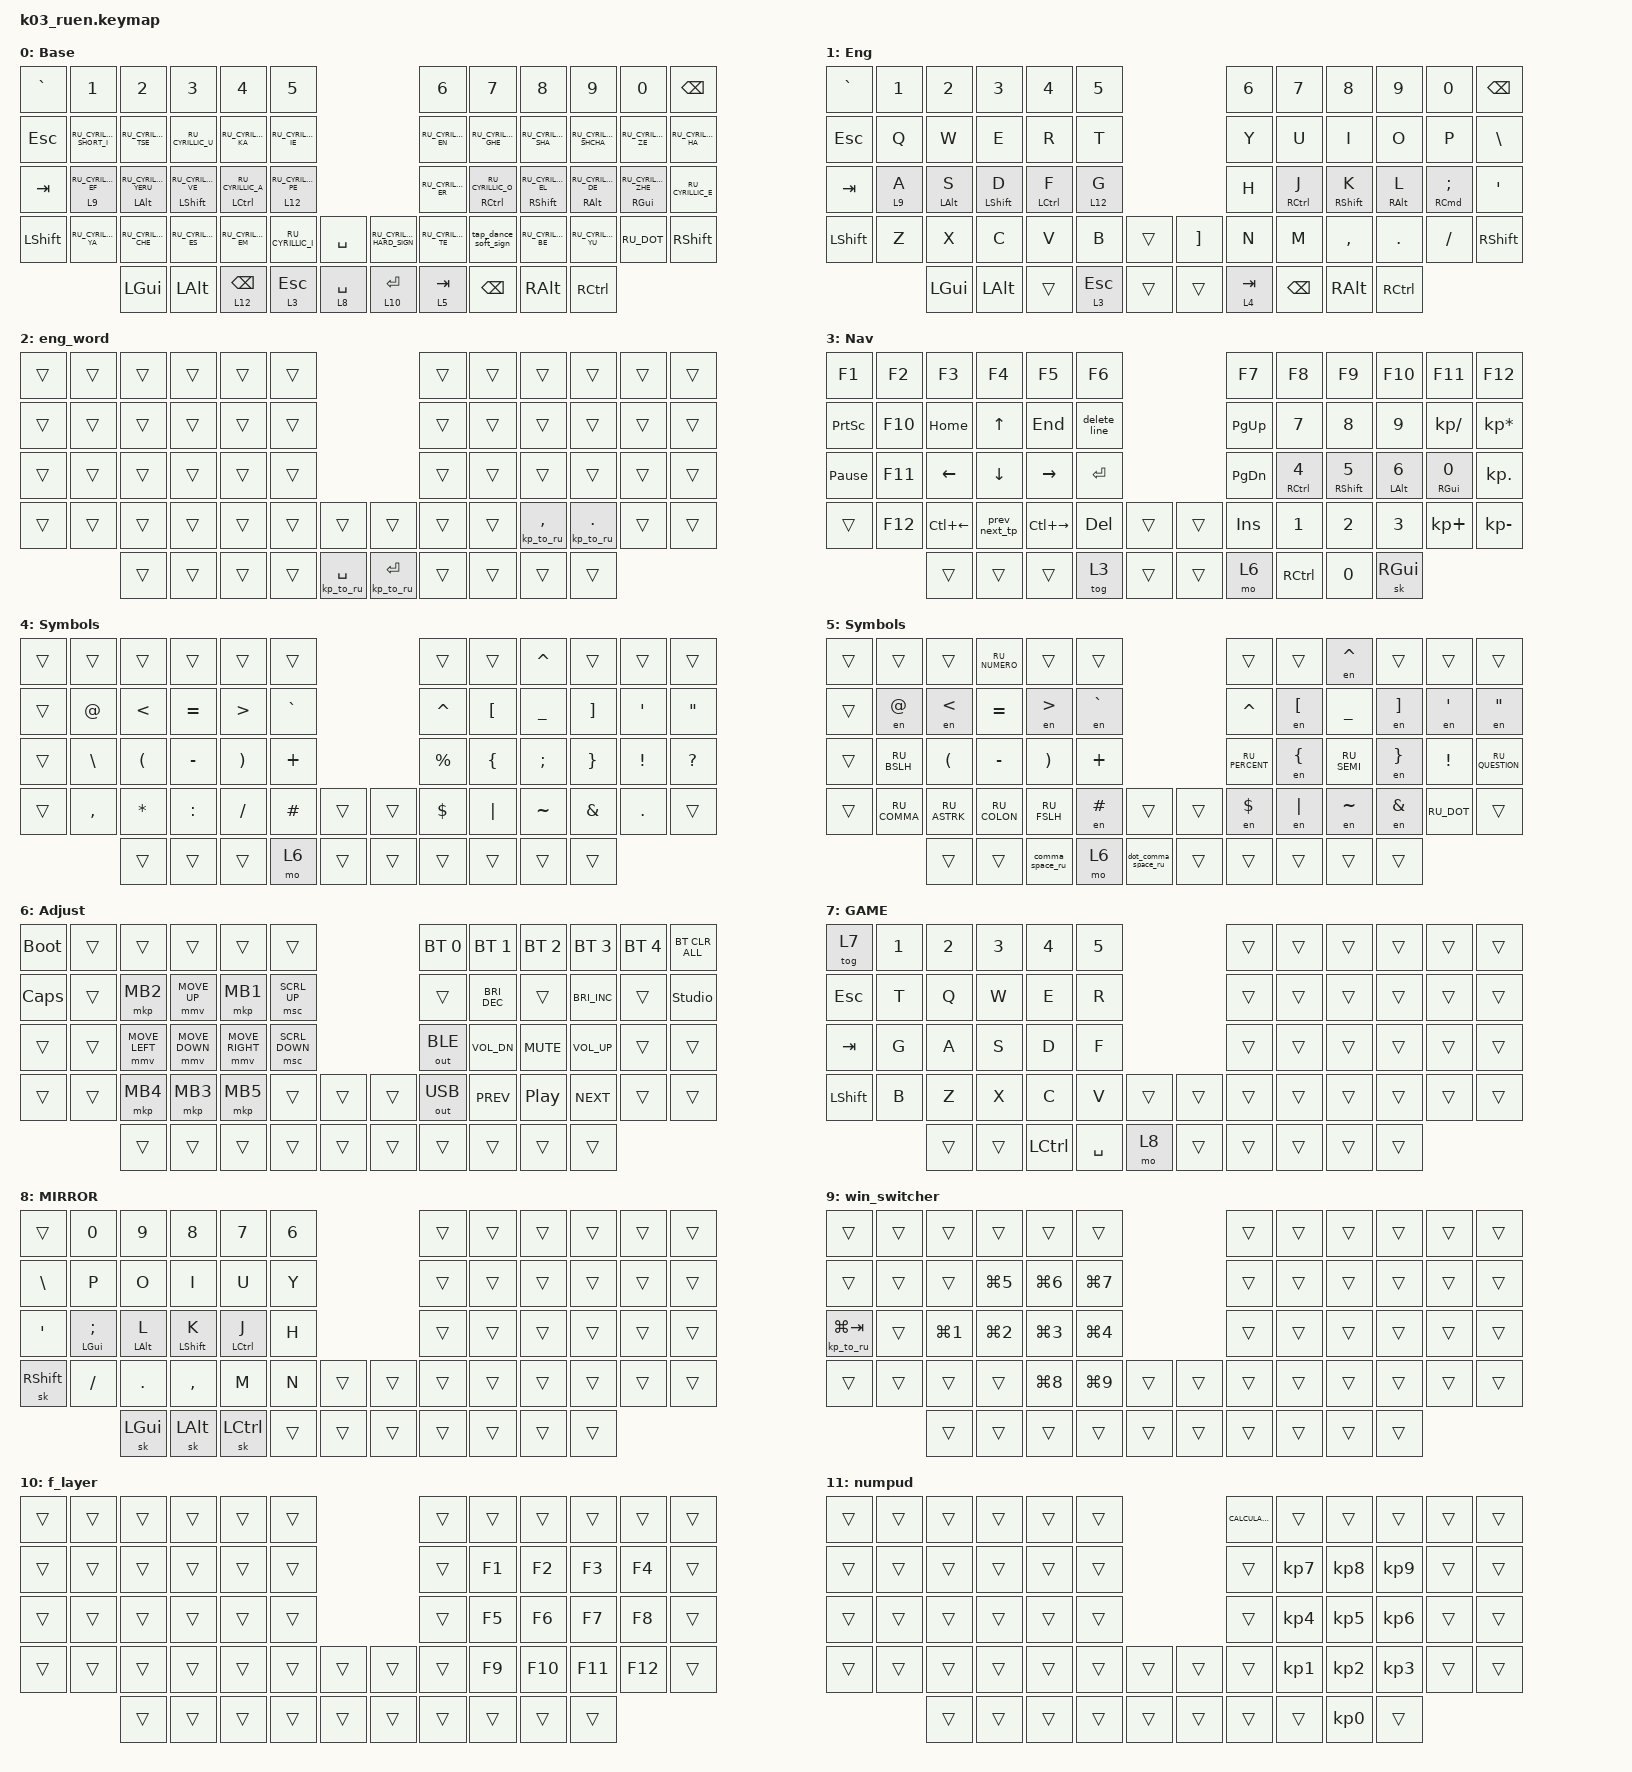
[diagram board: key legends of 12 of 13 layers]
#include "keys_ru.h"
#include <behaviors.dtsi>
#include <dt-bindings/zmk/bt.h>
#include <dt-bindings/zmk/keys.h>
#include <dt-bindings/zmk/outputs.h>
#include <dt-bindings/zmk/pointing.h>

&lt { flavor = "hold-preferred"; };

&mt { quick-tap-ms = <175>; };

/ {
    behaviors {
        enc_vol: enc_vol {
            compatible = "zmk,behavior-sensor-rotate";
            label = "ENC_VOL";
            #sensor-binding-cells = <0>;
            bindings = <&kp C_VOL_UP>, <&kp C_VOL_DN>;
        };

        l_st: l_st {
            compatible = "zmk,behavior-hold-tap";
            label = "L_ST";
            bindings = <&mo>, <&sk>;

            #binding-cells = <2>;
            tapping-term-ms = <200>;
        };

        prev_next: prev_next {
            compatible = "zmk,behavior-sensor-rotate";
            label = "PREV_NEXT";
            #sensor-binding-cells = <0>;
            bindings = <&mkp MB5>, <&mkp MB4>;
        };

        tap_dance_soft_sign: tap_dance_soft_sign {
            compatible = "zmk,behavior-tap-dance";
            label = "TAP_DANCE_SOFT_SIGN";
            #binding-cells = <0>;
            bindings = <&kp RU_CYRILLIC_SOFT_SIGN>, <&kp RU_CYRILLIC_HARD_SIGN>;
        };

        dot_comma_space_ru: dot_comma_space_ru {
            compatible = "zmk,behavior-tap-dance";
            label = "DOT_COMMA_SPACE_RU";
            #binding-cells = <0>;
            bindings = <&new_sentense_ru>, <&comma_space_ru>;
        };

        hml: home_row_mod_left {
            compatible = "zmk,behavior-hold-tap";
            label = "HML";
            bindings = <&kp>, <&kp>;

            #binding-cells = <2>;
            hold-trigger-on-release;
            hold-trigger-key-positions = <6 7 8 9 10 11 18 19 20 21 22 23 30 31 32 33 34 35 43 44 45 46 47 48 49 55 56 57 58 59 52 53 54>;
            flavor = "balanced";
            tapping-term-ms = <200>;
            quick-tap-ms = <175>;
            require-prior-idle-ms = <150>;
        };

        hmr: home_row_mod_right {
            compatible = "zmk,behavior-hold-tap";
            label = "HMR";
            bindings = <&kp>, <&kp>;

            #binding-cells = <2>;
            hold-trigger-on-release;
            flavor = "balanced";
            tapping-term-ms = <200>;
            quick-tap-ms = <175>;
            require-prior-idle-ms = <150>;
            hold-trigger-key-positions = <0 1 2 3 4 5 12 13 14 15 16 17 24 25 26 27 28 29 36 37 38 39 40 41 42 50 51 52 53 54 55 56 57>;
        };

        toggle_layer_on: toggle_layer_on {
            compatible = "zmk,behavior-toggle-layer";
            label = "TOGGLE_LAYER_ON";
            #binding-cells = <1>;
            toggle-mode = "on";
        };

        space_tp: space_tp {
            compatible = "zmk,behavior-tap-dance";
            label = "SPACE_TP";
            #binding-cells = <0>;
            bindings = <&lt 8 SPACE>, <&kp SPACE>;
        };

        lt_tap_pref: lt_tap_pref {
            compatible = "zmk,behavior-hold-tap";
            label = "LT_TAP_PREF";
            bindings = <&mo>, <&kp>;

            #binding-cells = <2>;
            flavor = "tap-preferred";
            tapping-term-ms = <200>;
            quick-tap-ms = <175>;
            require-prior-idle-ms = <150>;
        };

        sm_t: sm_t {
            compatible = "zmk,behavior-hold-tap";
            label = "SM_T";
            bindings = <&sk>, <&kp>;

            #binding-cells = <2>;
            flavor = "tap-preferred";
            tapping-term-ms = <200>;
            quick-tap-ms = <175>;
            require-prior-idle-ms = <150>;
        };

        caps_word_ru: caps_word_ru {
            compatible = "zmk,behavior-caps-word";
            label = "CAPS_WORD_RU";
            #binding-cells = <0>;
            continue-list = <UNDERSCORE MINUS BACKSPACE SEMI SQT COMMA DOT LBRC RBRC GRAVE>;
        };

        prev_next_tp: prev_next_tp {
            compatible = "zmk,behavior-tap-dance";
            label = "PREV_NEXT_TP";
            #binding-cells = <0>;
            bindings = <&mkp MB4>, <&mkp MB5>;
        };

        lt_quick_tap: lt_quick_tap {
            compatible = "zmk,behavior-hold-tap";
            label = "LT_QUICK_TAP";
            bindings = <&mo>, <&kp>;

            #binding-cells = <2>;
            tapping-term-ms = <200>;
            quick-tap-ms = <175>;
            flavor = "balanced";
        };
    };

    combos {
        compatible = "zmk,combos";

        cmben {
            bindings = <&layer_en>;
            key-positions = <40 41>;
            layers = <0>;
        };

        cmbru {
            bindings = <&layer_ru>;
            key-positions = <40 41>;
            layers = <1 2>;
        };

        cmb_game {
            bindings = <&tog 7>;
            key-positions = <0 1>;
            layers = <1 0>;
        };

        left_click_lcmb {
            bindings = <&mkp LCLK>;
            key-positions = <29 17>;
            layers = <1 0 7>;
        };

        right_click_lcmb {
            bindings = <&mkp RCLK>;
            key-positions = <15 27>;
            layers = <1 0 7>;
        };

        middle_click_lcmb {
            bindings = <&mkp MCLK>;
            key-positions = <28 16>;
            layers = <1 0 7>;
        };

        left_click_rcmb {
            bindings = <&mkp LCLK>;
            key-positions = <19 31>;
        };

        right_click_rcmb {
            bindings = <&mkp RCLK>;
            key-positions = <21 33>;
        };

        middle_click_rcmb {
            bindings = <&mkp MCLK>;
            key-positions = <20 32>;
        };

        eng_word_cmb {
            bindings = <&eng_word>;
            key-positions = <44 45>;
        };

        caps_word_cmb {
            bindings = <&caps_word>;
            key-positions = <36 49>;
            layers = <0 1 2>;
        };
    };

    macros {
        to_ru: to_ru {
            compatible = "zmk,behavior-macro";
            #binding-cells = <0>;
            bindings = <&kp LS(LC(N2))>;
            label = "TO_RU";
            wait-ms = <0>;
            tap-ms = <30>;
        };

        to_en: to_en {
            compatible = "zmk,behavior-macro";
            #binding-cells = <0>;
            bindings = <&kp LS(LC(N1))>;
            label = "TO_EN";
            wait-ms = <0>;
            tap-ms = <30>;
        };

        layer_en: layer_en {
            compatible = "zmk,behavior-macro";
            #binding-cells = <0>;
            bindings = <&to 1 &to_en>;
            label = "LAYER_EN";
            wait-ms = <0>;
            tap-ms = <30>;
        };

        layer_ru: layer_ru {
            compatible = "zmk,behavior-macro";
            #binding-cells = <0>;
            bindings = <&to 0 &to_ru>;
            label = "LAYER_RU";
            tap-ms = <30>;
            wait-ms = <0>;
        };

        en: en {
            compatible = "zmk,behavior-macro-one-param";
            #binding-cells = <1>;
            bindings =
                <&to_en>,
                <&macro_press>,
                <&macro_param_1to1 &kp MACRO_PLACEHOLDER>,
                <&macro_pause_for_release>,
                <&macro_release>,
                <&macro_param_1to1 &kp MACRO_PLACEHOLDER>,
                <&macro_tap>,
                <&to_ru>;

            label = "EN";
            wait-ms = <0>;
            tap-ms = <30>;
        };

        new_sentense_ru: new_sentense {
            compatible = "zmk,behavior-macro";
            #binding-cells = <0>;
            bindings = <&kp RU_DOT &kp SPACE &sk LEFT_SHIFT>;
            label = "NEW_SENTENSE";
        };

        delete_line: delete_line {
            compatible = "zmk,behavior-macro";
            #binding-cells = <0>;
            bindings = <&kp HOME &kp LS(END) &kp DELETE>;
            label = "DELETE_LINE";
            wait-ms = <10>;
            tap-ms = <10>;
        };

        comma_space_ru: comma_space_ru {
            compatible = "zmk,behavior-macro";
            #binding-cells = <0>;
            bindings = <&kp RU_COMMA &kp SPACE>;
            label = "COMMA_SPACE_RU";
        };

        kp_to_ru: kp_to_ru {
            compatible = "zmk,behavior-macro-one-param";
            #binding-cells = <1>;
            bindings = <&macro_param_1to1 &kp MACRO_PLACEHOLDER &layer_ru>;
            label = "KP_TO_RU";
        };

        eng_word: eng_word {
            compatible = "zmk,behavior-macro";
            #binding-cells = <0>;
            bindings = <&layer_en &tog 2>;
            label = "ENG_WORD";
        };
    };

    keymap {
        compatible = "zmk,keymap";

        ru {
            display-name = "Base";
            bindings = <
&kp GRAVE  &kp N1                         &kp N2                          &kp N3                          &kp N4                     &kp N5                                                                              &kp N6              &kp N7                    &kp N8                           &kp N9                    &kp N0                          &kp BSPC
&kp ESC    &kp RU_CYRILLIC_SHORT_I        &kp RU_CYRILLIC_TSE             &kp RU_CYRILLIC_U               &kp RU_CYRILLIC_KA         &kp RU_CYRILLIC_IE                                                                  &kp RU_CYRILLIC_EN  &kp RU_CYRILLIC_GHE       &kp RU_CYRILLIC_SHA              &kp RU_CYRILLIC_SHCHA     &kp RU_CYRILLIC_ZE              &kp RU_CYRILLIC_HA
&kp TAB    &lt_tap_pref 9 RU_CYRILLIC_EF  &hml LEFT_ALT RU_CYRILLIC_YERU  &hml LEFT_SHIFT RU_CYRILLIC_VE  &hml LCTRL RU_CYRILLIC_A   &lt_tap_pref 12 RU_CYRILLIC_PE                                                      &kp RU_CYRILLIC_ER  &hmr RCTRL RU_CYRILLIC_O  &hmr RIGHT_SHIFT RU_CYRILLIC_EL  &hmr RALT RU_CYRILLIC_DE  &hmr RIGHT_GUI RU_CYRILLIC_ZHE  &kp RU_CYRILLIC_E
&kp LSHFT  &kp RU_CYRILLIC_YA             &kp RU_CYRILLIC_CHE             &kp RU_CYRILLIC_ES              &kp RU_CYRILLIC_EM         &kp RU_CYRILLIC_I               &kp SPACE                &kp RU_CYRILLIC_HARD_SIGN  &kp RU_CYRILLIC_TE  &tap_dance_soft_sign      &kp RU_CYRILLIC_BE               &kp RU_CYRILLIC_YU        &kp RU_DOT                      &kp RIGHT_SHIFT
                                          &kp LGUI                        &kp LALT                        &lt_tap_pref 12 BACKSPACE  &lt 3 ESC                       &lt_quick_tap 8 SPACE    &lt 10 ENTER               &lt 5 TAB           &kp BACKSPACE             &kp RALT                         &kp RCTRL
            >;

            sensor-bindings =
                <&inc_dec_kp UP_ARROW DOWN_ARROW>,
                <&inc_dec_kp TAB LS(TAB)>;
        };

        en {
            bindings = <
&kp GRAVE  &kp N1            &kp N2       &kp N3        &kp N4        &kp N5                                 &kp N6     &kp N7         &kp N8        &kp N9       &kp N0          &kp BSPC
&kp ESC    &kp Q             &kp W        &kp E         &kp R         &kp T                                  &kp Y      &kp U          &kp I         &kp O        &kp P           &kp BSLH
&kp TAB    &lt_tap_pref 9 A  &hml LALT S  &hml LSHFT D  &hml LCTRL F  &lt_tap_pref 12 G                      &kp H      &hmr RCTRL J   &hmr RSHFT K  &hmr RALT L  &hmr RCMD SEMI  &kp SQT
&kp LSHFT  &kp Z             &kp X        &kp C         &kp V         &kp B              &trans    &kp RBKT  &kp N      &kp M          &kp COMMA     &kp DOT      &kp FSLH        &kp RSHFT
                             &kp LGUI     &kp LALT      &trans        &lt 3 ESC          &trans    &trans    &lt 4 TAB  &kp BACKSPACE  &kp RALT      &kp RCTRL
            >;

            display-name = "Eng";
            sensor-bindings =
                <&inc_dec_kp UP_ARROW DOWN_ARROW>,
                <&inc_dec_kp TAB LS(TAB)>;
        };

        eng_word {
            bindings = <
&trans  &trans  &trans  &trans  &trans  &trans                                      &trans  &trans  &trans           &trans         &trans  &trans
&trans  &trans  &trans  &trans  &trans  &trans                                      &trans  &trans  &trans           &trans         &trans  &trans
&trans  &trans  &trans  &trans  &trans  &trans                                      &trans  &trans  &trans           &trans         &trans  &trans
&trans  &trans  &trans  &trans  &trans  &trans  &trans             &trans           &trans  &trans  &kp_to_ru COMMA  &kp_to_ru DOT  &trans  &trans
                &trans  &trans  &trans  &trans  &kp_to_ru SPACE    &kp_to_ru ENTER  &trans  &trans  &trans           &trans
            >;
        };

        nav {
            bindings = <
&kp F1           &kp F2   &kp F3        &kp F4         &kp F5         &kp F6                          &kp F7     &kp F8         &kp F9          &kp F10           &kp F11            &kp F12
&kp PRINTSCREEN  &kp F10  &kp HOME      &kp UP         &kp END        &delete_line                    &kp PG_UP  &kp N7         &kp N8          &kp N9            &kp KP_SLASH       &kp KP_ASTERISK
&kp PAUSE_BREAK  &kp F11  &kp LEFT      &kp DOWN       &kp RIGHT      &kp RET                         &kp PG_DN  &hmr RCTRL N4  &hmr RSHIFT N5  &hmr LEFT_ALT N6  &hmr RIGHT_GUI N0  &kp KP_DOT
&trans           &kp F12  &kp LC(LEFT)  &prev_next_tp  &kp LC(RIGHT)  &kp DEL       &trans    &trans  &kp INS    &kp N1         &kp N2          &kp N3            &kp KP_PLUS        &kp KP_MINUS
                          &trans        &trans         &trans         &tog 3        &trans    &trans  &mo 6      &kp RCTRL      &kp N0          &sk RIGHT_GUI
            >;

            display-name = "Nav";
            sensor-bindings = <&inc_dec_kp LC(Y) LC(Z)>, <&prev_next>;
        };

        sym_en {
            bindings = <
&trans  &trans     &trans    &trans     &trans    &trans                       &trans      &trans    &kp CARET  &trans    &trans    &trans
&trans  &kp AT     &kp LT    &kp EQUAL  &kp GT    &kp GRAVE                    &kp CARET   &kp LBKT  &kp UNDER  &kp RBKT  &kp APOS  &kp DOUBLE_QUOTES
&trans  &kp BSLH   &kp LPAR  &kp MINUS  &kp RPAR  &kp PLUS                     &kp PRCNT   &kp LBRC  &kp SEMI   &kp RBRC  &kp EXCL  &kp QUESTION
&trans  &kp COMMA  &kp STAR  &kp COLON  &kp FSLH  &kp HASH   &trans    &trans  &kp DOLLAR  &kp PIPE  &kp TILDE  &kp AMPS  &kp DOT   &trans
                   &trans    &trans     &trans    &mo 6      &trans    &trans  &trans      &trans    &trans     &trans
            >;

            display-name = "Symbols";
            sensor-bindings = <&inc_dec_kp RIGHT_ARROW LEFT_ARROW>;
        };

        sym_ru {
            display-name = "Symbols";
            bindings = <
&trans  &trans        &trans        &kp RU_NUMERO  &trans           &trans                                    &trans          &trans    &en CARET    &trans    &trans            &trans
&trans  &en AT        &en LT        &kp EQUAL      &en GT           &en GRAVE                                 &kp CARET       &en LBKT  &kp UNDER    &en RBKT  &en SINGLE_QUOTE  &en DOUBLE_QUOTES
&trans  &kp RU_BSLH   &kp LPAR      &kp MINUS      &kp RPAR         &kp PLUS                                  &kp RU_PERCENT  &en LBRC  &kp RU_SEMI  &en RBRC  &kp EXCL          &kp RU_QUESTION
&trans  &kp RU_COMMA  &kp RU_ASTRK  &kp RU_COLON   &kp RU_FSLH      &en HASH   &trans                 &trans  &en DOLLAR      &en PIPE  &en TILDE    &en AMPS  &kp RU_DOT        &trans
                      &trans        &trans         &comma_space_ru  &mo 6      &dot_comma_space_ru    &trans  &trans          &trans    &trans       &trans
            >;

            sensor-bindings = <&inc_dec_kp RIGHT_ARROW LEFT_ARROW>;
        };

        adj {
            bindings = <
&bootloader   &trans  &trans          &trans          &trans           &trans                            &bt BT_SEL 0  &bt BT_SEL 1          &bt BT_SEL 2      &bt BT_SEL 3          &bt BT_SEL 4  &bt BT_CLR_ALL
&kp CAPSLOCK  &trans  &mkp MB2        &mmv MOVE_UP    &mkp MB1         &msc SCRL_UP                      &trans        &kp C_BRIGHTNESS_DEC  &trans            &kp C_BRIGHTNESS_INC  &trans        &studio_unlock
&trans        &trans  &mmv MOVE_LEFT  &mmv MOVE_DOWN  &mmv MOVE_RIGHT  &msc SCRL_DOWN                    &out OUT_BLE  &kp C_VOL_DN          &kp C_MUTE        &kp C_VOL_UP          &trans        &trans
&trans        &trans  &mkp MB4        &mkp MB3        &mkp MB5         &trans          &trans    &trans  &out OUT_USB  &kp C_PREV            &kp C_PLAY_PAUSE  &kp C_NEXT            &trans        &trans
                      &trans          &trans          &trans           &trans          &trans    &trans  &trans        &trans                &trans            &trans
            >;

            display-name = "Adjust";
            sensor-bindings =
                <&inc_dec_kp C_BRIGHTNESS_INC C_BRIGHTNESS_DEC>,
                <&enc_vol>;
        };

        GAME {
            bindings = <
&tog 7     &kp N1  &kp N2  &kp N3  &kp N4     &kp N5                       &trans  &trans  &trans  &trans  &trans  &trans
&kp ESC    &kp T   &kp Q   &kp W   &kp E      &kp R                        &trans  &trans  &trans  &trans  &trans  &trans
&kp TAB    &kp G   &kp A   &kp S   &kp D      &kp F                        &trans  &trans  &trans  &trans  &trans  &trans
&kp LSHFT  &kp B   &kp Z   &kp X   &kp C      &kp V      &trans    &trans  &trans  &trans  &trans  &trans  &trans  &trans
                   &trans  &trans  &kp LCTRL  &kp SPACE  &mo 8     &trans  &trans  &trans  &trans  &trans
            >;
        };

        MIRROR {
            bindings = <
&trans     &kp N0               &kp N9            &kp N8              &kp N7         &kp N6                    &trans  &trans  &trans  &trans  &trans  &trans
&kp BSLH   &kp P                &kp O             &kp I               &kp U          &kp Y                     &trans  &trans  &trans  &trans  &trans  &trans
&kp APOS   &sm_t LEFT_GUI SEMI  &sm_t LEFT_ALT L  &sm_t LEFT_SHIFT K  &sm_t LCTRL J  &kp H                     &trans  &trans  &trans  &trans  &trans  &trans
&sk RSHFT  &kp FSLH             &kp DOT           &kp COMMA           &kp M          &kp N   &trans    &trans  &trans  &trans  &trans  &trans  &trans  &trans
                                &sk LEFT_GUI      &sk LEFT_ALT        &sk LCTRL      &trans  &trans    &trans  &trans  &trans  &trans  &trans
            >;

            sensor-bindings = <&inc_dec_kp 0 0>;
        };

        win_switcher {
            bindings = <
&trans             &trans  &trans      &trans      &trans      &trans                        &trans  &trans  &trans  &trans  &trans  &trans
&trans             &trans  &trans      &kp LG(N5)  &kp LG(N6)  &kp LG(N7)                    &trans  &trans  &trans  &trans  &trans  &trans
&kp_to_ru LG(TAB)  &trans  &kp LG(N1)  &kp LG(N2)  &kp LG(N3)  &kp LG(N4)                    &trans  &trans  &trans  &trans  &trans  &trans
&trans             &trans  &trans      &trans      &kp LG(N8)  &kp LG(N9)  &trans    &trans  &trans  &trans  &trans  &trans  &trans  &trans
                           &trans      &trans      &trans      &trans      &trans    &trans  &trans  &trans  &trans  &trans
            >;
        };

        f_layer {
            bindings = <
&trans  &trans  &trans  &trans  &trans  &trans                    &trans  &trans  &trans   &trans   &trans   &trans
&trans  &trans  &trans  &trans  &trans  &trans                    &trans  &kp F1  &kp F2   &kp F3   &kp F4   &trans
&trans  &trans  &trans  &trans  &trans  &trans                    &trans  &kp F5  &kp F6   &kp F7   &kp F8   &trans
&trans  &trans  &trans  &trans  &trans  &trans  &trans    &trans  &trans  &kp F9  &kp F10  &kp F11  &kp F12  &trans
                &trans  &trans  &trans  &trans  &trans    &trans  &trans  &trans  &trans   &trans
            >;
        };

        numpud {
            bindings = <
&trans  &trans  &trans  &trans  &trans  &trans                    &kp K_CALCULATOR  &trans           &trans           &trans           &trans  &trans
&trans  &trans  &trans  &trans  &trans  &trans                    &trans            &kp KP_NUMBER_7  &kp KP_NUMBER_8  &kp KP_NUMBER_9  &trans  &trans
&trans  &trans  &trans  &trans  &trans  &trans                    &trans            &kp KP_NUMBER_4  &kp KP_NUMBER_5  &kp KP_NUMBER_6  &trans  &trans
&trans  &trans  &trans  &trans  &trans  &trans  &trans    &trans  &trans            &kp KP_NUMBER_1  &kp KP_NUMBER_2  &kp KP_NUMBER_3  &trans  &trans
                &trans  &trans  &trans  &trans  &trans    &trans  &trans            &trans           &kp KP_NUMBER_0  &trans
            >;
        };

        sticky_mods_layer {
            bindings = <
&trans  &trans        &trans     &trans     &trans     &trans                    &trans  &trans  &trans  &trans  &trans  &trans
&trans  &trans        &trans     &trans     &trans     &trans                    &trans  &trans  &trans  &trans  &trans  &trans
&trans  &sk LEFT_GUI  &sk LALT   &sk LSHFT  &sk LCTRL  &trans                    &trans  &trans  &trans  &trans  &trans  &trans
&trans  &trans        &kp LC(X)  &kp LC(C)  &kp LC(V)  &trans  &trans    &trans  &trans  &trans  &trans  &trans  &trans  &trans
                      &trans     &trans     &trans     &trans  &trans    &trans  &trans  &trans  &trans  &trans
            >;
        };
    };
};
